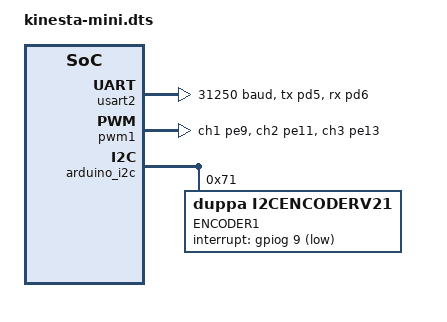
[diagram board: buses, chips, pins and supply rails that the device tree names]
// MIDI DIN connector
// Tx on PD5 / Rx on PD6
midi_din_uart: &usart2 {
    status = "okay";
    pinctrl-0 = <&usart2_tx_pd5 &usart2_rx_pd6>;
    pinctrl-names = "default";
    current-speed = <31250>;
};

&pwm1 {
    pinctrl-0 = <
        &tim1_ch1_pe9
        &tim1_ch2_pe11
        &tim1_ch3_pe13
    >;
    pinctrl-names = "default";
};

&arduino_i2c {
    encoder1: encoder@71 {
        compatible = "duppa,i2cencoderv21";
        label = "ENCODER1";
        reg = <0x71>;
        // PG9 (D0)
        interrupt-gpios = <&gpiog 9 GPIO_ACTIVE_LOW>;
    };
};

// Disable usart6 (to free up D0/D1)
&usart6 {
    status = "disabled";
};

/ {
    kinesta {
        #address-cells = <1>;
        #size-cells = <0>;

        touchpad1: touchpad_1 {
            compatible = "kinesta,rgb-touchpad-pwm";
            // PF13 (D7)
            touch-gpios = <&gpiof 13 GPIO_ACTIVE_HIGH>;

            // Red:   PE9 (D6)
            // Green: PE13 (D3)
            // Blue:  P11 (D5)
            pwm-names = "red", "green", "blue";
            pwms = <&pwm1 1 0 PWM_POLARITY_INVERTED>,
                   <&pwm1 3 0 PWM_POLARITY_INVERTED>,
                   <&pwm1 2 0 PWM_POLARITY_INVERTED>;
        };

        touchpad2: touchpad_2 {
            compatible = "kinesta,rgb-touchpad-gpio";
            // PC13 (Nucleo-144 User button)
            touch-gpios = <&gpioc 13 GPIO_ACTIVE_HIGH>;

            // PB14: (Nucleo-144 RED LED)
            r-gpios = <&gpiob 14 GPIO_ACTIVE_HIGH>;
            // PB0: (Nucleo-144 GREEN LED)
            g-gpios = <&gpiob 0 GPIO_ACTIVE_HIGH>;
            // PB7: (Nucleo-144 BLUE LED)
            b-gpios = <&gpiob 7 GPIO_ACTIVE_HIGH>;
        };

        slice1 {
            label = "SLICE1";
            compatible = "kinesta,functional-block";
            midi-cc-group = <0x10>;

            primary-touchpad = <&touchpad1>;
            secondary-touchpad = <&touchpad2>;
            encoder = <&encoder1>;
            distance-sensor = <&vl53l0x_c>;
        };
    };
};
